AUTOSAR XML (schema 00051)
package /Tier1/ARPlatform1/Pcpt_CMscA  # Modeling show case for primitive measurement and calculation.
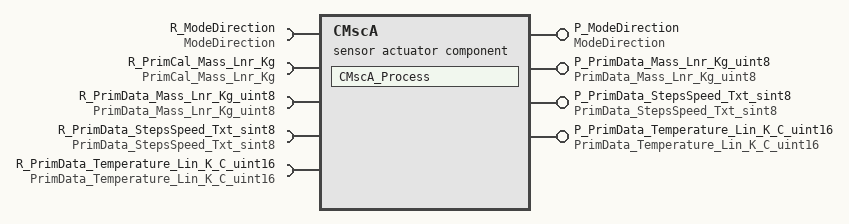
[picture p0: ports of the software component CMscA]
  sensor actuator sw component type CMscA  # Modeling show case for primitive measurement and calculation.
    4 x provide port:
      P_ModeDirection: mode-switch-sender-com-spec{mode-group=ModeDirection, queue-length=1}, provided-interface=ModeDirection  # Mode to indicate a direction
      P_PrimData_Mass_Lnr_Kg_uint8: nonqueued-sender-com-spec{data-element=PrimData_Mass_Lnr_Kg_uint8, init-value=0 kg}, provided-interface=PrimData_Mass_Lnr_Kg_uint8  # Mass in kilogram
      P_PrimData_StepsSpeed_Txt_sint8: provided-interface=PrimData_StepsSpeed_Txt_sint8  # Stepwise speed indication
      P_PrimData_Temperature_Lin_K_C_uint16: nonqueued-sender-com-spec{data-element=PrimData_Temperature_Lin_K_C_uint16, init-value=273.1484375 K}, provided-interface=PrimData_Temperature_Lin_K_C_uint16  # Temperature 1 in Kelvin but displayed as degree Celsius
    5 x require port:
      R_ModeDirection: mode-switch-receiver-com-spec{enhanced-mode-api=true, supports-asynchronous-mode-switch=false}, required-interface=ModeDirection  # Mode to indicate a direction
      R_PrimCal_Mass_Lnr_Kg: required-interface=PrimCal_Mass_Lnr_Kg  # Primitive calibration parameter for minimum egg mass.
      R_PrimData_Mass_Lnr_Kg_uint8: required-interface=PrimData_Mass_Lnr_Kg_uint8  # Mass in kilogram
      R_PrimData_StepsSpeed_Txt_sint8: required-interface=PrimData_StepsSpeed_Txt_sint8  # Stepwise speed indication
      R_PrimData_Temperature_Lin_K_C_uint16: required-interface=PrimData_Temperature_Lin_K_C_uint16  # Temperature 1 in Kelvin but displayed as degree Celsius
    behavior CMscA: constant-value-mapping=CMscA_DefaultConstantMapping, data-type-mapping=DefaultDataTypeMapping, handle-termination-and-restart=NO-SUPPORT, included-data-type-set{data-type=speedSteps, literal-prefix=speedSteps_}
      runnable CMscA_Process: sw-addr-method=CODE_10MS, can-be-invoked-concurrently=true, mode-access-point=R_ModeDirection.ModeDirection  # cyclic process
        data-read-access:
          access R_PrimData_Mass_Lnr_Kg_uint8_PrimData_Mass_Lnr_Kg_uint8: accessed-variable=R_PrimData_Mass_Lnr_Kg_uint8.PrimData_Mass_Lnr_Kg_uint8
          access R_PrimData_StepsSpeed_Txt_sint8_PrimData_StepsSpeed_Txt_sint8: accessed-variable=R_PrimData_StepsSpeed_Txt_sint8.PrimData_StepsSpeed_Txt_sint8
          access R_PrimData_Temperature_Lin_K_C_uint16_PrimData_Temperature_Lin_K_C_uint16: accessed-variable=R_PrimData_Temperature_Lin_K_C_uint16.PrimData_Temperature_Lin_K_C_uint16
        data-write-access:
          access P_PrimData_Mass_Lnr_Kg_uint8_PrimData_Mass_Lnr_Kg_uint8: accessed-variable=P_PrimData_Mass_Lnr_Kg_uint8.PrimData_Mass_Lnr_Kg_uint8
          access P_PrimData_StepsSpeed_Txt_sint8_PrimData_StepsSpeed_Txt_sint8: accessed-variable=P_PrimData_StepsSpeed_Txt_sint8.PrimData_StepsSpeed_Txt_sint8
          access P_PrimData_Temperature_Lin_K_C_uint16_PrimData_Temperature_Lin_K_C_uint16: accessed-variable=P_PrimData_Temperature_Lin_K_C_uint16.PrimData_Temperature_Lin_K_C_uint16
        mode switch point P_ModeDirection_ModeDirection: mode-group=P_ModeDirection.ModeDirection
        parameter access R_PrimCal_Mass_Lnr_Kg_PrimCal_Mass_Lnr_Kg: accessed-parameter=R_PrimCal_Mass_Lnr_Kg.PrimCal_Mass_Lnr_Kg
      swc service dependency CMscA_NvBlock0: assigned-ports=role-based-port-assignment={port-prototype=CMscA/P_PrimData_StepsSpeed_Txt_sint8, role=NvDataPort}  # Nv data of egg cooking time determination
        service-needs:
          nv block needs CMscA_NvBlock0: calc-ram-block-crc=true, check-static-block-id=false, n-data-sets=0, readonly=false, reliability=ERROR-DETECTION, resistant-to-changed-sw=false, restore-at-start=true, store-at-shutdown=true, write-only-once=false, writing-frequency=1000, writing-priority=LOW
  constant specification mapping set CMscA_DefaultConstantMapping
  swc implementation CMscA_impl: programming-language=C, vendor-id=8, behavior=CMscA
    code-descriptors:
      code CMscA: artifact-descriptors=autosar-engineering-object={short-label=CMscA, category=SWSRC, domain=ARPlatform1}
    resource consumption CMscA_rc
      memory section CODE_10MS: sw-addrmethod=CODE_10MS
  parameter sw component type CMscA_par: constant-mapping=CMscA_DefaultConstantMapping, data-type-mapping=DefaultDataTypeMapping  # Modeling show case for primitive measurement and calculation.
    provide port P_PrimCal_Mass_Lnr_Kg: parameter-provide-com-spec{init-value=0 kg, parameter=PrimCal_Mass_Lnr_Kg}, provided-interface=PrimCal_Mass_Lnr_Kg  # Primitive calibration parameter for minimum egg mass.
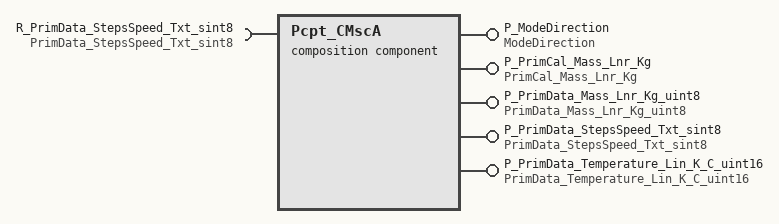
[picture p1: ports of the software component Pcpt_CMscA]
  composition sw component type Pcpt_CMscA: data-type-mapping=DefaultDataTypeMapping  # Modeling show case for primitive measurement and calculation.
    5 x provide port:
      P_ModeDirection: provided-interface=ModeDirection  # Mode to indicate a direction
      P_PrimCal_Mass_Lnr_Kg: provided-interface=PrimCal_Mass_Lnr_Kg  # Primitive calibration parameter for minimum egg mass.
      P_PrimData_Mass_Lnr_Kg_uint8: provided-interface=PrimData_Mass_Lnr_Kg_uint8  # Mass in kilogram
      P_PrimData_StepsSpeed_Txt_sint8: provided-interface=PrimData_StepsSpeed_Txt_sint8  # Stepwise speed indication
      P_PrimData_Temperature_Lin_K_C_uint16: provided-interface=PrimData_Temperature_Lin_K_C_uint16  # Temperature 1 in Kelvin but displayed as degree Celsius
    require port R_PrimData_StepsSpeed_Txt_sint8: required-interface=PrimData_StepsSpeed_Txt_sint8  # Stepwise speed indication
    component CMscA: type=CMscA
    component CMscA_par: type=CMscA_par
    connect CMscA.P_ModeDirection -> CMscA.R_ModeDirection
    delegate CMscA.P_ModeDirection <-> outer port Pcpt_CMscA/P_ModeDirection
    connect CMscA.P_PrimData_Mass_Lnr_Kg_uint8 -> CMscA.R_PrimData_Mass_Lnr_Kg_uint8
    delegate CMscA.P_PrimData_Mass_Lnr_Kg_uint8 <-> outer port Pcpt_CMscA/P_PrimData_Mass_Lnr_Kg_uint8
    delegate CMscA.P_PrimData_StepsSpeed_Txt_sint8 <-> outer port Pcpt_CMscA/P_PrimData_StepsSpeed_Txt_sint8
    connect CMscA.P_PrimData_Temperature_Lin_K_C_uint16 -> CMscA.R_PrimData_Temperature_Lin_K_C_uint16
    delegate CMscA.P_PrimData_Temperature_Lin_K_C_uint16 <-> outer port Pcpt_CMscA/P_PrimData_Temperature_Lin_K_C_uint16
    connect CMscA_par.P_PrimCal_Mass_Lnr_Kg -> CMscA.R_PrimCal_Mass_Lnr_Kg
    delegate CMscA_par.P_PrimCal_Mass_Lnr_Kg <-> outer port Pcpt_CMscA/P_PrimCal_Mass_Lnr_Kg
    delegate CMscA.R_PrimData_StepsSpeed_Txt_sint8 <-> outer port Pcpt_CMscA/R_PrimData_StepsSpeed_Txt_sint8
